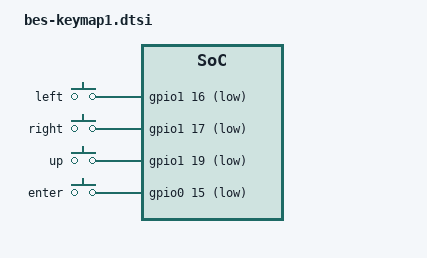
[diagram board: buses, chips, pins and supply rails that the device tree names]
/*
 * Copyright (C) 2012 Texas Instruments Incorporated - http://www.ti.com/
 *
 * This program is free software; you can redistribute it and/or modify
 * it under the terms of the GNU General Public License version 2 as
 * published by the Free Software Foundation.
 */

&ocp {
	P9_15_pinmux {
		/* gpio1[16] */
		status = "disabled";
	};
	P9_16_pinmux {
		/* gpio1[19] */
		status = "disabled";
	};
	P9_23_pinmux {
		/* gpio1[17] */
		status = "disabled";
	};
	P9_24_pinmux {
		/* gpio0[15] */
		status = "disabled";
	};
	P9_30_pinmux {
		/* gpio3[16] */
		status = "disabled";
	};
};

&am33xx_pinmux {
	/* lcd4-01-00a1/4dcape-43(t) */
	bes_keymap1_pins: pinmux_bes_keymap1_pins {
		pinctrl-single,pins = <
			0x040 0x2f  /* KEY_LEFT gpmc_a0.gpio1_16, INPUT | PULLDIS | MODE7 */
			0x044 0x2f  /* KEY_RIGHT gpmc_a1.gpio1_17, INPUT | PULLDIS | MODE7 */
			0x04c 0x2f  /* KEY_UP gpmc_a3.gpio1_19, INPUT | PULLDIS | MODE7 */
			/* AWH - Conflict 0x198 0x2f */  /* KEY_DOWN mcasp0_axr0.gpio3_16, INPUT | PULLDIS | MODE7 */
			0x184 0x2f  /* KEY_ENTER uart1_txd.gpio0_15, INPUT | PULLDIS | MODE7 */
		>;
	};
};

/ {
	gpio_keys {
		compatible = "gpio-keys";
		pinctrl-names = "default";
		pinctrl-0 = <&bes_keymap1_pins>;

		#address-cells = <1>;
		#size-cells = <0>;

		button@1 {
			debounce_interval = <50>;
			linux,code = <105>;
			label = "left";
			gpios = <&gpio1 16 0x1>;
			gpio-key,wakeup;
			autorepeat;
		};
		button@2 {
			debounce_interval = <50>;
			linux,code = <106>;
			label = "right";
			gpios = <&gpio1 17 0x1>;
			gpio-key,wakeup;
			autorepeat;
		};
		button@3 {
			debounce_interval = <50>;
			linux,code = <103>;
			label = "up";
			gpios = <&gpio1 19 0x1>;
			gpio-key,wakeup;
			autorepeat;
		};
		/* AWH - Conflict with audio revb cape */
		/*button@4 {
			debounce_interval = <50>;
			linux,code = <108>;
			label = "down";
			gpios = <&gpio3 16 0x1>;
			gpio-key,wakeup;
			autorepeat;
		};*/
		button@5 {
			debounce_interval = <50>;
			linux,code = <28>;
			label = "enter";
			gpios = <&gpio0 15 0x1>;
			gpio-key,wakeup;
		};
	};
};
